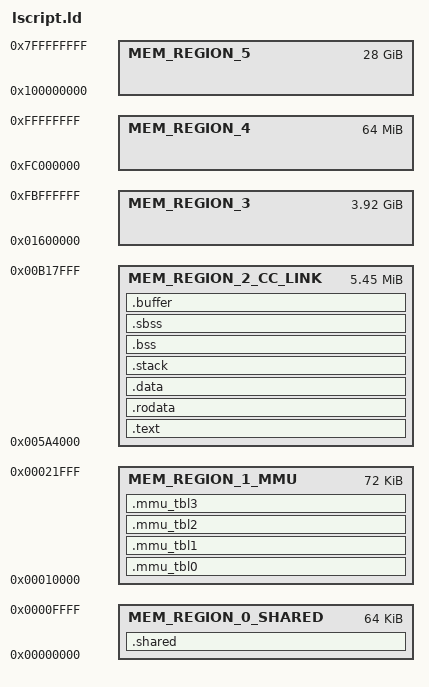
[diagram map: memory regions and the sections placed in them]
/*
 * Automatically generated by AutoMetalBench
 * Please make sure to define the attributes especified for each descriptor
 */

_STACK_SIZE = 0x1000;
_BUFFER_SIZE = 0x200000;

MEMORY
{
	MEM_REGION_0_SHARED :	 ORIGIN = 0x0, LENGTH = 0x10000
	MEM_REGION_1_MMU :	 ORIGIN = 0x10000, LENGTH = 0x12000
	MEM_REGION_2_CC_LINK :	 ORIGIN = 0x5a4000, LENGTH = 0x574000
	MEM_REGION_3 :	 ORIGIN = 0x1600000, LENGTH = 0xfaa00000
	MEM_REGION_4 :	 ORIGIN = 0xfc000000, LENGTH = 0x4000000
	MEM_REGION_5 :	 ORIGIN = 0x100000000, LENGTH = 0x700000000
}

ENTRY(_boot)

SECTIONS
{
.shared (NOLOAD) : {
	. = ALIGN(0x8);
	__shared_start = .;
	. += 65536;
	__shared_end = .;
} > MEM_REGION_0_SHARED
.mmu_tbl0 (NOLOAD) : {
	. = ALIGN(4096);
	__mmu_tbl0_start = .;
	*(.mmu_tbl0)
	__mmu_tbl0_end = .;
} > MEM_REGION_1_MMU
.mmu_tbl1 (NOLOAD) : {
	. = ALIGN(4096);
	__mmu_tbl1_start = .;
	*(.mmu_tbl1)
	__mmu_tbl1_end = .;
} > MEM_REGION_1_MMU
.mmu_tbl2 (NOLOAD) : {
	. = ALIGN(4096);
	__mmu_tbl2_start = .;
	*(.mmu_tbl2)
	__mmu_tbl2_end = .;
} > MEM_REGION_1_MMU
.mmu_tbl3 (NOLOAD) : {
	. = ALIGN(4096);
	__mmu_tbl3_start = .;
	*(.mmu_tbl3)
	__mmu_tbl3_end = .;
} > MEM_REGION_1_MMU

. = ALIGN(64);
__loader_vma = .;

.text : {
	__ld_text = LOADADDR(.text);
	__text_start = .;
	. = ALIGN(64);
	KEEP (*(.vectors))
	*(.handlers)
	*(.boot)
	*(.text)
	*(.text.*)
	__text_end = .;
} > MEM_REGION_2_CC_LINK
.rodata : {
	__ld_rodata = LOADADDR(.rodata);
	__rodata_start = .;
	. = ALIGN(64);
	*(.rodata)
	*(.rodata.*)
	__rodata_end = .;
} > MEM_REGION_2_CC_LINK
.data : {
	__ld_data = LOADADDR(.data);
	__data_start = .;
	. = ALIGN(64);
	*(.data)
	*(.data.*)
	__data_end = .;
} > MEM_REGION_2_CC_LINK
.stack (NOLOAD) : {
	. = ALIGN(64);
	__stack_start = .;
	. += _STACK_SIZE;
	__stack_end = .;
} > MEM_REGION_2_CC_LINK
.bss (NOLOAD) : {
	. = ALIGN(64);
	__bss_start = .;
	*(.bss)
	*(.bss.*)
	*(.gnu.linkonce.b.*)
	*(COMMON)
	. = ALIGN(64);
	__bss_end = .;
} > MEM_REGION_2_CC_LINK
.sbss (NOLOAD) : {
	. = ALIGN(64);
	__sbss_start = .;
	*(.sbss)
	*(.sbss.*)
	*(.gnu.linkonce.sb.*)
	. = ALIGN(64);
	__sbss_end = .;
} > MEM_REGION_2_CC_LINK
/* This section is only useful for the standard benchmarks */
.buffer (NOLOAD) : {
	. = ALIGN(64);
	__buffer_start = .;
	. += _BUFFER_SIZE;
	__buffer_end = .;
} > MEM_REGION_2_CC_LINK
}
